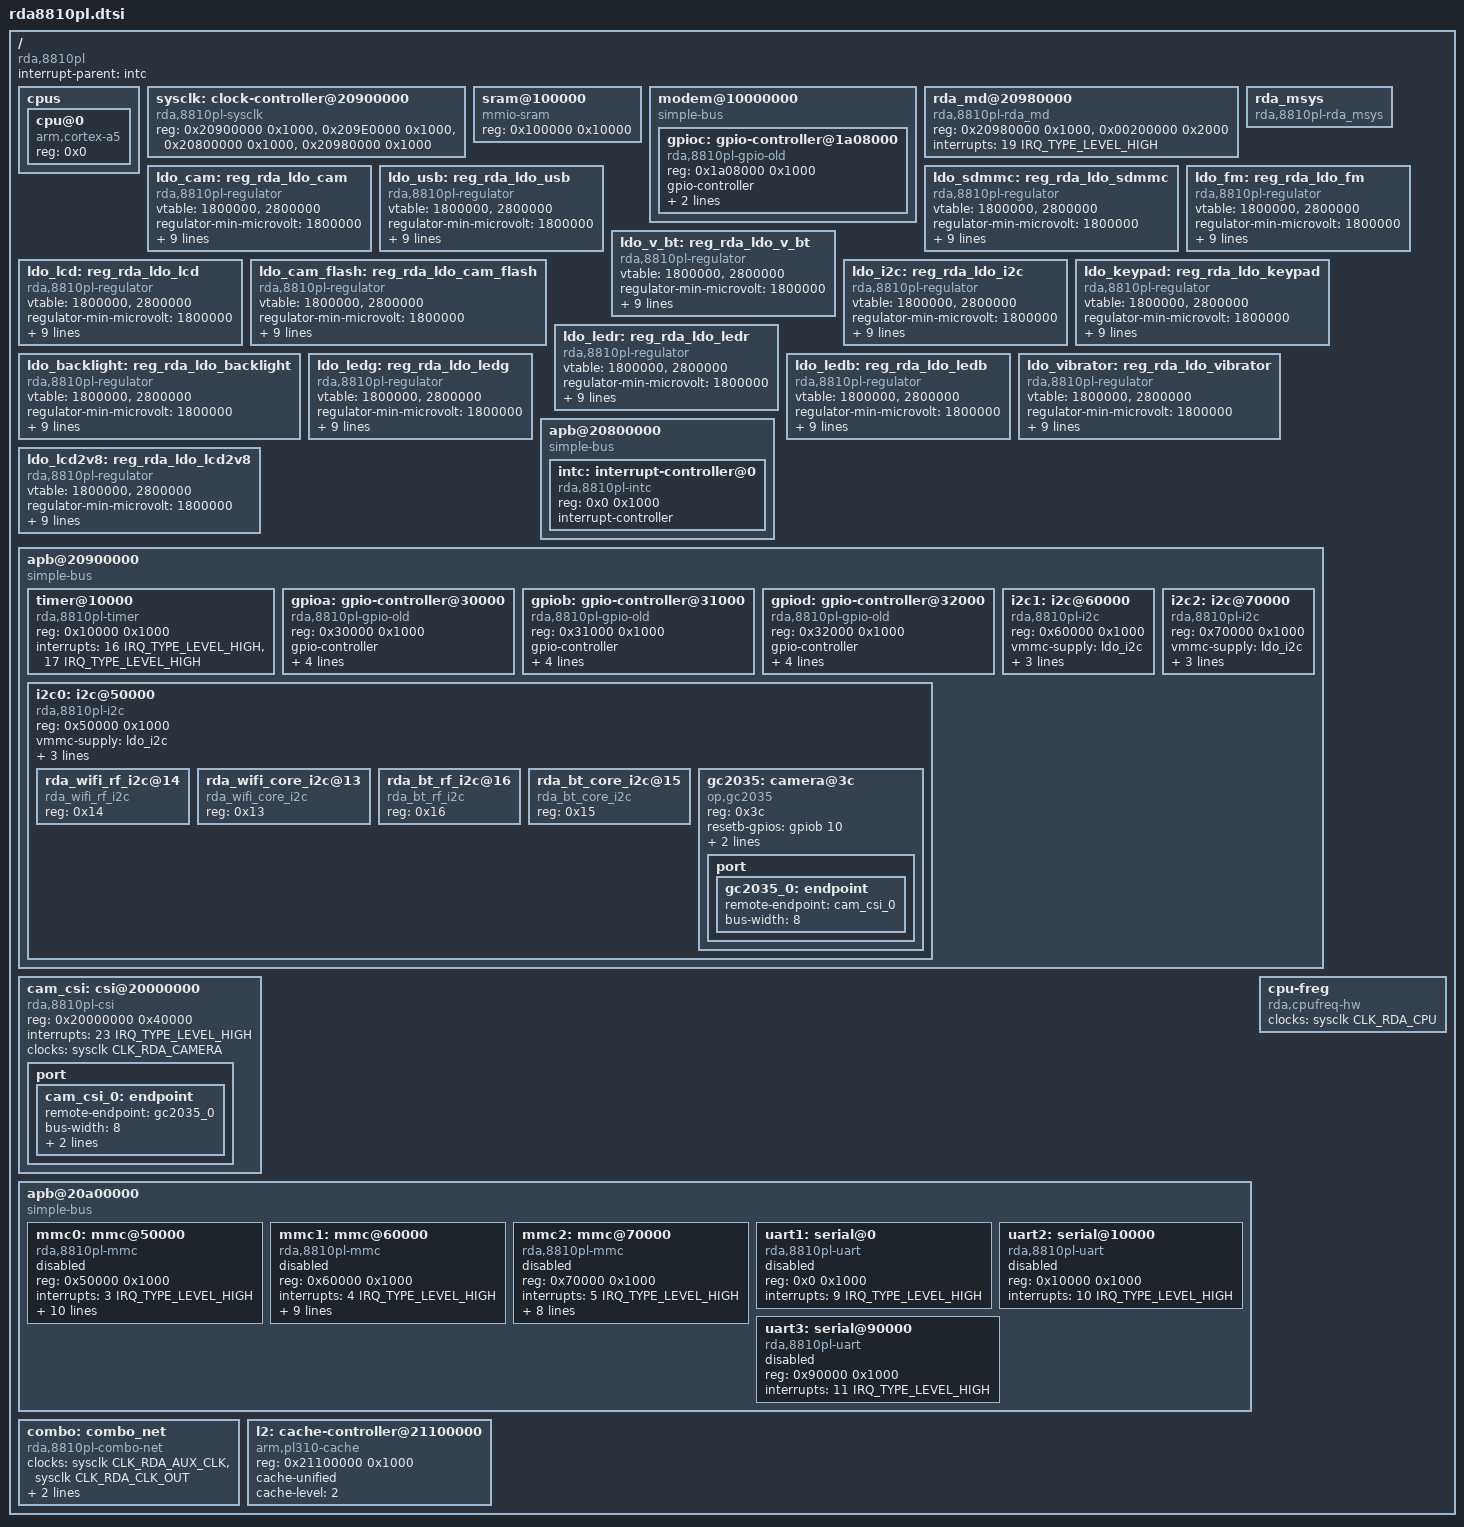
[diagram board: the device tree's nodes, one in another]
// SPDX-License-Identifier: (GPL-2.0+ OR MIT)
/*
 * RDA8810PL SoC
 *
 * Copyright (c) 2017 Andreas Färber
 * Copyright (c) 2018 Manivannan Sadhasivam
 */

#include <dt-bindings/interrupt-controller/irq.h>
#include <dt-bindings/rda/md_sys_enums.h>
#include <dt-bindings/rda/rda_clk_list.h>
#include <dt-bindings/gpio/gpio.h>

/ {
	compatible = "rda,8810pl";
	interrupt-parent = <&intc>;
	#address-cells = <1>;
	#size-cells = <1>;

	cpus {
		#address-cells = <1>;
		#size-cells = <0>;

		cpu@0 {
			device_type = "cpu";
			compatible = "arm,cortex-a5";
			reg = <0x0>;
		};
	};
	
	sysclk:clock-controller@20900000 {
			compatible = "rda,8810pl-sysclk";
			reg = <0x20900000 0x1000>,
			<0x209E0000 0x1000>,
			<0x20800000 0x1000>,
			<0x20980000 0x1000>;
			#clock-cells = <1>;
		};

	sram@100000 {
		compatible = "mmio-sram";
		reg = <0x100000 0x10000>;
		#address-cells = <1>;
		#size-cells = <1>;
		ranges;
	};

	modem@10000000 {
		compatible = "simple-bus";
		#address-cells = <1>;
		#size-cells = <1>;
		ranges = <0x0 0x10000000 0xfffffff>;

		gpioc: gpio-controller@1a08000 {
			compatible = "rda,8810pl-gpio-old";
			reg = <0x1a08000 0x1000>;
			gpio-controller;
			#gpio-cells = <2>;
			ngpios = <32>;
			
			id = <3>;
		};
	};
	
	
	
	rda_md@20980000 {
		compatible = "rda,8810pl-rda_md";
		reg = <0x20980000 0x1000>,
		<0x00200000 0x2000>;
		interrupts = <19 IRQ_TYPE_LEVEL_HIGH>;
		};
		
	rda_msys {
		compatible = "rda,8810pl-rda_msys";
		};
		

	ldo_cam:reg_rda_ldo_cam {
		compatible = "rda,8810pl-regulator";
		
		vtable = <1800000>,
				<2800000>;
		
		regulator-min-microvolt = <1800000>;
		regulator-max-microvolt = <2800000>;
		regulator_type = <0>; // 0 - REGULATOR_VOLTAGE, 1 - REGULATOR_CURRENT;
		id = <0>;
		pm_id = <1>;
		msys_cmd = <SYS_PM_CMD_EN>;
		valid_modes_mask = <(0x2 | 0x8)>;
		valid_ops_mask = <(0x8 | 0x1 | 0x4)>;
		suply_consumer_name = "v_cam";
		def_val = <1800000>;
		};
		
	ldo_usb:reg_rda_ldo_usb {
		compatible = "rda,8810pl-regulator";
		
		vtable = <1800000>,
				<2800000>;
		
		regulator-min-microvolt = <1800000>;
		regulator-max-microvolt = <2800000>;
		regulator_type = <0>; // 0 - REGULATOR_VOLTAGE, 1 - REGULATOR_CURRENT;
		id = <1>;
		pm_id = <6>; 
		msys_cmd = <SYS_PM_CMD_EN>;
		valid_modes_mask = <(0x2 | 0x8)>;
		valid_ops_mask = <(0x8 | 0x1 | 0x4)>;
		suply_consumer_name = "v_usb";
		def_val = <1800000>;
		};
		
	ldo_sdmmc:reg_rda_ldo_sdmmc {
		compatible = "rda,8810pl-regulator";
		
		vtable = <1800000>,
				<2800000>;

		regulator-min-microvolt = <1800000>;
		regulator-max-microvolt = <2800000>;
		regulator_type = <0>; // 0 - REGULATOR_VOLTAGE, 1 - REGULATOR_CURRENT;
		id = <2>;
		pm_id = <7>;
		msys_cmd = <SYS_PM_CMD_EN>;
		valid_modes_mask = <(0x2 | 0x8)>;
		valid_ops_mask = <(0x8 | 0x1 | 0x4)>;
		suply_consumer_name = "v_sdmmc";
		def_val = <2800000>;
		};
		
	ldo_fm:reg_rda_ldo_fm {
		compatible = "rda,8810pl-regulator";
		
		vtable = <1800000>,
				<2800000>;
		
		regulator-min-microvolt = <1800000>;
		regulator-max-microvolt = <2800000>;
		regulator_type = <0>; // 0 - REGULATOR_VOLTAGE, 1 - REGULATOR_CURRENT;
		id = <3>;
		pm_id = <8>; //8
		msys_cmd = <SYS_PM_CMD_EN>;
		valid_modes_mask = <(0x2 | 0x8)>;
		valid_ops_mask = <(0x8 | 0x1 | 0x4)>;
		suply_consumer_name = "v_fm";
		def_val = <1800000>;
		};
		
	ldo_v_bt:reg_rda_ldo_v_bt {
		compatible = "rda,8810pl-regulator";
		
		vtable = <1800000>,
				<2800000>;

		regulator-min-microvolt = <1800000>;
		regulator-max-microvolt = <2800000>;
		regulator_type = <0>; // 0 - REGULATOR_VOLTAGE, 1 - REGULATOR_CURRENT;
		id = <4>;
		pm_id = <10>;
		msys_cmd = <SYS_PM_CMD_EN>;
		valid_modes_mask = <(0x2 | 0x8)>;
		valid_ops_mask = <(0x8 | 0x1 | 0x4)>;
		suply_consumer_name = "v_bt";
		def_val = <1800000>;
		};
		
	ldo_lcd:reg_rda_ldo_lcd {
		compatible = "rda,8810pl-regulator";
		
		vtable = <1800000>,
				<2800000>;
		
		regulator-min-microvolt = <1800000>;
		regulator-max-microvolt = <2800000>;
		regulator_type = <0>; // 0 - REGULATOR_VOLTAGE, 1 - REGULATOR_CURRENT;
		id = <5>;
		pm_id = <12>;//12
		msys_cmd = <SYS_PM_CMD_EN>;
		valid_modes_mask = <(0x2 | 0x8)>;
		valid_ops_mask = <(0x8 | 0x1 | 0x4)>;
		suply_consumer_name = "v_lcd";
		def_val = <1800000>;
		};
		
	ldo_cam_flash:reg_rda_ldo_cam_flash {
		compatible = "rda,8810pl-regulator";
		
		vtable = <1800000>,
				<2800000>;
		
		regulator-min-microvolt = <1800000>;
		regulator-max-microvolt = <2800000>;
		regulator_type = <0>; // 0 - REGULATOR_VOLTAGE, 1 - REGULATOR_CURRENT;
		id = <6>;
		pm_id = <11>;
		msys_cmd = <SYS_PM_CMD_EN>;
		valid_modes_mask = <(0x2 | 0x8)>;
		valid_ops_mask = <(0x8 | 0x1 | 0x4)>;
		suply_consumer_name = "v_camflash";
		def_val = <1800000>;
		};
		
	
	ldo_i2c:reg_rda_ldo_i2c {
		compatible = "rda,8810pl-regulator";
		
		vtable = <1800000>,
				<2800000>;

		regulator-min-microvolt = <1800000>;
		regulator-max-microvolt = <2800000>;
		regulator_type = <0>; // 0 - REGULATOR_VOLTAGE, 1 - REGULATOR_CURRENT;
		id = <7>;
		pm_id = <13>;
		msys_cmd = <SYS_PM_CMD_EN>;
		valid_modes_mask = <(0x2 | 0x8)>;
		valid_ops_mask = <(0x8 | 0x1 | 0x4)>;
		suply_consumer_name = "v_i2c";
		def_val = <2800000>;
		};
		
	ldo_keypad:reg_rda_ldo_keypad {
		compatible = "rda,8810pl-regulator";
		
		vtable = <1800000>,
				<2800000>;

		regulator-min-microvolt = <1800000>;
		regulator-max-microvolt = <2800000>;
		regulator_type = <0>; // 0 - REGULATOR_VOLTAGE, 1 - REGULATOR_CURRENT;
		id = <8>;
		pm_id = <3>;
		msys_cmd = <SYS_PM_CMD_EN>;
		valid_modes_mask = <(0x2 | 0x8)>;
		valid_ops_mask = <( 0x1 | 0x4)>;
		suply_consumer_name = "v_keypad";
		def_val = <1800000>;
		};
		
	ldo_backlight:reg_rda_ldo_backlight {
		compatible = "rda,8810pl-regulator";
		
		vtable = <1800000>,
				<2800000>;

		regulator-min-microvolt = <1800000>;
		regulator-max-microvolt = <2800000>;
		regulator_type = <1>; // 0 - REGULATOR_VOLTAGE, 1 - REGULATOR_CURRENT;
		id = <9>;
		pm_id = <2>;
		msys_cmd = <SYS_PM_CMD_EN>;
		valid_modes_mask = <(0x2 | 0x8)>;
		valid_ops_mask = <( 0x1 | 0x4)>;
		suply_consumer_name = "v_backlight";
		def_val = <1800000>;
		};
		
	ldo_ledr:reg_rda_ldo_ledr {
		compatible = "rda,8810pl-regulator";
		
		vtable = <1800000>,
				<2800000>;

		regulator-min-microvolt = <1800000>;
		regulator-max-microvolt = <2800000>;
		regulator_type = <0>; // 0 - REGULATOR_VOLTAGE, 1 - REGULATOR_CURRENT;
		id = <10>;
		pm_id = <4>;
		msys_cmd = <SYS_PM_CMD_EN>;
		valid_modes_mask = <(0x2 | 0x8)>;
		valid_ops_mask = <( 0x1 | 0x4)>;
		suply_consumer_name = "v_ledr";
		def_val = <1800000>;
		};
		
	ldo_ledg:reg_rda_ldo_ledg {
		compatible = "rda,8810pl-regulator";
		
		vtable = <1800000>,
				<2800000>;

		regulator-min-microvolt = <1800000>;
		regulator-max-microvolt = <2800000>;
		regulator_type = <0>; // 0 - REGULATOR_VOLTAGE, 1 - REGULATOR_CURRENT;
		id = <11>;
		pm_id = <5>;
		msys_cmd = <SYS_PM_CMD_EN>;
		valid_modes_mask = <(0x2 | 0x8)>;
		valid_ops_mask = <( 0x1 | 0x4)>;
		suply_consumer_name = "v_ledg";
		def_val = <1800000>;
		};
		
	ldo_ledb:reg_rda_ldo_ledb {
		compatible = "rda,8810pl-regulator";
		
		vtable = <1800000>,
				<2800000>;

		regulator-min-microvolt = <1800000>;
		regulator-max-microvolt = <2800000>;
		regulator_type = <0>; // 0 - REGULATOR_VOLTAGE, 1 - REGULATOR_CURRENT;
		id = <12>;
		pm_id = <0>;
		msys_cmd = <SYS_PM_CMD_EN>;
		valid_modes_mask = <(0x2 | 0x8)>;
		valid_ops_mask = <( 0x1 | 0x4)>;
		suply_consumer_name = "v_ledb";
		def_val = <1800000>;
		};
		
	ldo_vibrator:reg_rda_ldo_vibrator {
		compatible = "rda,8810pl-regulator";
		
		vtable = <1800000>,
				<2800000>;

		regulator-min-microvolt = <1800000>;
		regulator-max-microvolt = <2800000>;
		regulator_type = <0>; // 0 - REGULATOR_VOLTAGE, 1 - REGULATOR_CURRENT;
		id = <13>;
		pm_id = <9>;
		msys_cmd = <SYS_PM_CMD_EN>;
		valid_modes_mask = <(0x2 | 0x8)>;
		valid_ops_mask = <( 0x1 | 0x4)>;
		suply_consumer_name = "v_vibrator";
		def_val = <1800000>;
		};
	
ldo_lcd2v8:reg_rda_ldo_lcd2v8 {
		compatible = "rda,8810pl-regulator";
		
		vtable = <1800000>,
				<2800000>;

		regulator-min-microvolt = <1800000>;
		regulator-max-microvolt = <2800000>;
		regulator_type = <0>; // 0 - REGULATOR_VOLTAGE, 1 - REGULATOR_CURRENT;
		id = <14>;
		pm_id = <14>;
		msys_cmd = <SYS_PM_CMD_EN>;
		valid_modes_mask = <(0x2 | 0x8)>;
		valid_ops_mask = <( 0x1 | 0x4)>;
		suply_consumer_name = "v_lcd2v8";
		def_val = <1800000>;
		};
		


	apb@20800000 {
		compatible = "simple-bus";
		#address-cells = <1>;
		#size-cells = <1>;
		ranges = <0x0 0x20800000 0x100000>;

		intc: interrupt-controller@0 {
			compatible = "rda,8810pl-intc";
			reg = <0x0 0x1000>;
			interrupt-controller;
			#interrupt-cells = <2>;
		};
	};
	
	

	apb@20900000 {
		compatible = "simple-bus";
		#address-cells = <1>;
		#size-cells = <1>;
		ranges = <0x0 0x20900000 0x100000>;
		
		

		timer@10000 {
			compatible = "rda,8810pl-timer";
			reg = <0x10000 0x1000>;
			interrupts = <16 IRQ_TYPE_LEVEL_HIGH>,
				     <17 IRQ_TYPE_LEVEL_HIGH>;
			interrupt-names = "hwtimer", "ostimer";
		};

		gpioa: gpio-controller@30000 {
			
			compatible = "rda,8810pl-gpio-old";
			reg = <0x30000 0x1000>;
			gpio-controller;
			#gpio-cells = <2>;
			ngpios = <32>;
			interrupt-controller;
			#interrupt-cells = <2>;
			interrupts = <12 IRQ_TYPE_LEVEL_HIGH>;
			
			id = <0>;
		};

		gpiob: gpio-controller@31000 {
			
			compatible = "rda,8810pl-gpio-old";
			reg = <0x31000 0x1000>;
			gpio-controller;
			#gpio-cells = <2>;
			ngpios = <32>;
			interrupt-controller;
			#interrupt-cells = <2>;
			interrupts = <13 IRQ_TYPE_LEVEL_HIGH>;
			
			id = <1>;
		};

		gpiod: gpio-controller@32000 {
			
			compatible = "rda,8810pl-gpio-old";
			reg = <0x32000 0x1000>;
			gpio-controller;
			#gpio-cells = <2>;
			ngpios = <32>;
			interrupt-controller;
			#interrupt-cells = <2>;
			interrupts = <14 IRQ_TYPE_LEVEL_HIGH>;
			
			id = <2>;
		};
		
		i2c0: i2c@50000 {
			compatible = "rda,8810pl-i2c";
			reg = <0x50000 0x1000>;
			vmmc-supply = <&ldo_i2c>;
			clocks = <&sysclk CLK_RDA_APB1>;
			clock-frequency = <100000>; //100000 orig
			
			id = <0>;
			#address-cells = <0x1>;
			#size-cells = <0>;
			status = "okay";
			
				rda_wifi_rf_i2c@14 {
					compatible = "rda_wifi_rf_i2c";
					reg = <0x14>;
					status = "okay";
				};
				
				rda_wifi_core_i2c@13 {
					compatible = "rda_wifi_core_i2c";
					reg = <0x13>;
					status = "okay";
				};
				
				rda_bt_rf_i2c@16 {
					compatible = "rda_bt_rf_i2c";
					reg = <0x16>;
					status = "okay";
				};
				
				rda_bt_core_i2c@15 {
					compatible = "rda_bt_core_i2c";
					reg = <0x15>;
					status = "okay";
				};
				
				gc2035: camera@3c {
					compatible = "op,gc2035";
					reg = <0x3c>;
					resetb-gpios = <&gpiob 10 GPIO_ACTIVE_HIGH>;
					pwdn-gpios = <&gpiob 11 GPIO_ACTIVE_LOW>;
					//clocks = <&sysclk CLK_RDA_CAMERA>;
					vmmc-supply = <&ldo_cam>;

					port {
						gc2035_0: endpoint {
							remote-endpoint = <&cam_csi_0>;
							bus-width = <8>;
						};
					};
				};
				
			
		};
		
		i2c1: i2c@60000 {
			compatible = "rda,8810pl-i2c";
			reg = <0x60000 0x1000>;
			vmmc-supply = <&ldo_i2c>;
			clocks = <&sysclk CLK_RDA_APB1>;
			clock-frequency = <400000>;
			id = <1>;
			
			#address-cells = <0x1>;
			#size-cells = <0>;
			
			
		};
		
		i2c2: i2c@70000 {
			compatible = "rda,8810pl-i2c";
			reg = <0x70000 0x1000>;
			vmmc-supply = <&ldo_i2c>;
			clocks = <&sysclk CLK_RDA_APB1>;
			clock-frequency = <200000>;
			
			id = <2>;
		};
	};
	
	cam_csi: csi@20000000 {
				compatible = "rda,8810pl-csi";
				reg = <0x20000000 0x40000>;
				interrupts = <23 IRQ_TYPE_LEVEL_HIGH>;
				clocks = <&sysclk CLK_RDA_CAMERA>;
				port {
					cam_csi_0: endpoint {
							remote-endpoint = <&gc2035_0>;
							bus-width = <8>;
							vsync-active = <1>;
							hsync-active = <1>;
					};
				};
			};

	apb@20a00000 {
		compatible = "simple-bus";
		#address-cells = <1>;
		#size-cells = <1>;
		ranges = <0x0 0x20a00000 0x100000>;
		
		mmc0: mmc@50000 {
			compatible = "rda,8810pl-mmc";
			reg = <0x50000 0x1000>;
			interrupts = <3 IRQ_TYPE_LEVEL_HIGH>;
			detpin-gpios = <&gpiob 4 GPIO_ACTIVE_HIGH>;
			vmmc-supply = <&ldo_sdmmc>;
			clocks = <&sysclk CLK_RDA_APB2>;
			
			mmc_id = <0>;
			max-frequency = <30000000>;
			caps = <(1 << 0)>;
			pm_caps = <0>;
			sys_suspend = <1>;
			clk_inv = <1>;
			mclk_adj = <1>;
			
			status = "disabled";
		};
		mmc1: mmc@60000 {
			compatible = "rda,8810pl-mmc";
			reg = <0x60000 0x1000>;
			interrupts = <4 IRQ_TYPE_LEVEL_HIGH>;
			eirqpin-gpios = <&gpiob 2 GPIO_ACTIVE_HIGH>;
			clocks = <&sysclk CLK_RDA_APB2>;
			
			mmc_id = <1>;
			max-frequency = <60000000>;  //20000000 orig
			caps = <((1 << 0) | (1 << 3))>;
			pm_caps = <(1 << 0)>;
			sys_suspend = <1>;
			clk_inv = <1>;
			mclk_adj = <3>;
			
			status = "disabled";
		};
		mmc2: mmc@70000 {
			compatible = "rda,8810pl-mmc";
			reg = <0x70000 0x1000>;
			interrupts = <5 IRQ_TYPE_LEVEL_HIGH>;
			clocks = <&sysclk CLK_RDA_APB2>;
			
			mmc_id = <2>;
			max-frequency = <30000000>;
			caps = <((1 << 6) | (1 << 8))>;
			pm_caps = <0>;
			sys_suspend = <0>;
			clk_inv = <0>;
			mclk_adj = <0>;
			
			status = "disabled";
		};

		uart1: serial@0 {
			compatible = "rda,8810pl-uart";
			reg = <0x0 0x1000>;
			interrupts = <9 IRQ_TYPE_LEVEL_HIGH>;
			status = "disabled";
		};

		uart2: serial@10000 {
			compatible = "rda,8810pl-uart";
			reg = <0x10000 0x1000>;
			interrupts = <10 IRQ_TYPE_LEVEL_HIGH>;
			status = "disabled";
		};

		uart3: serial@90000 {
			compatible = "rda,8810pl-uart";
			reg = <0x90000 0x1000>;
			interrupts = <11 IRQ_TYPE_LEVEL_HIGH>;
			status = "disabled";
		};
		
		
	};
	
	combo:combo_net 
	{
		compatible = "rda,8810pl-combo-net";
		clocks = <&sysclk CLK_RDA_AUX_CLK>, <&sysclk CLK_RDA_CLK_OUT>;
		clock-names = "rda_aux", "rda_out";
		wakepin-gpios = <&gpiob 1 GPIO_ACTIVE_HIGH>;
		vbt-supply = <&ldo_v_bt>;
	};
	
	cpu-freg
	{
		compatible = "rda,cpufreq-hw";
		clocks = <&sysclk CLK_RDA_CPU>;
	};
	

	l2: cache-controller@21100000 
	{
		compatible = "arm,pl310-cache";
		reg = <0x21100000 0x1000>;
		cache-unified;
		cache-level = <2>;
	};
};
